# STM32L4P5xx register map
File version: 1.0
Registers are 32-bit, read-write, reset 0x0 unless marked. A register's access mark holds for its fields unless they carry their own. Offsets are from the block's base; [hi:lo] are bit positions; {n}, {i} and the like mark numbered series; 'fields as' and 'values as' point back to an identical list.

## HASH
Base 0x50060400
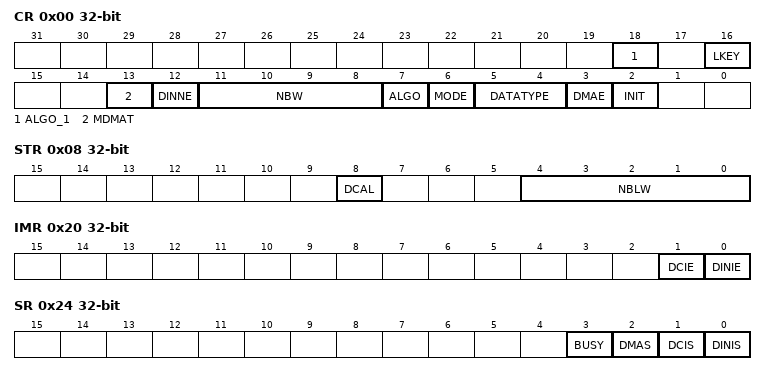
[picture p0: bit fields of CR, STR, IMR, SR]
0x00 CR — HASH control register
  [18] ALGO_1, [16] LKEY, [13] MDMAT, [12] DINNE, [11:8] NBW, [7] ALGO, [6] MODE, [5:4] DATATYPE, [3] DMAE, [2] INIT
0x04 DIN — HASH data input register
0x08 STR — HASH start register
  [8] DCAL, [4:0] NBLW
{0xC+4i} HR{i} (i=0..4) — HASH digest registers
0x20 IMR — HASH interrupt enable register
  [1] DCIE, [0] DINIE
0x24 SR — HASH status register
  [3] BUSY, [2] DMAS, [1] DCIS, [0] DINIS
{0xF8+4i} CSR{i} (i=0..53) — HASH context swap registers
{0x310+4i} DIGEST_HR{i} (i=0..7) — HASH digest registers

## RNG
Base 0x50060800
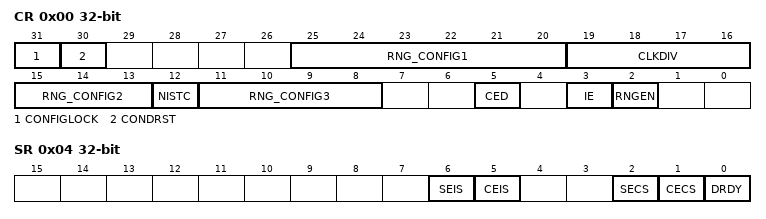
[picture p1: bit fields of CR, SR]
0x00 CR — RNG control register
  [31] CONFIGLOCK
  [30] CONDRST
  [25:20] RNG_CONFIG1
  [19:16] CLKDIV
    0=BY_1 (No clock division); 1=BY_2 (2 RNG clock cycles per internal RNG clock); 2=BY_4 (4 RNG clock cycles per internal RNG clock); 3=BY_8 (8 RNG clock cycles per internal RNG clock); 4=BY_16 (16 RNG clock cycles per internal RNG clock); 5=BY_32 (32 RNG clock cycles per internal RNG clock); 6=BY_64 (64 RNG clock cycles per internal RNG clock); 7=BY_128 (128 RNG clock cycles per internal RNG clock); 8=BY_256 (256 RNG clock cycles per internal RNG clock); 9=BY_512 (512 RNG clock cycles per internal RNG clock); 10=BY_1024 (1024 RNG clock cycles per internal RNG clock); 11=BY_2048 (2048 RNG clock cycles per internal RNG clock); 12=BY_4096 (4096 RNG clock cycles per internal RNG clock); 13=BY_8192 (8192 RNG clock cycles per internal RNG clock); 14=BY_16384 (16384 RNG clock cycles per internal RNG clock); 15=BY_32768 (32768 RNG clock cycles per internal RNG clock)
  [15:13] RNG_CONFIG2
  [12] NISTC
  [11:8] RNG_CONFIG3
  [5] CED
  [3] IE
  [2] RNGEN
0x04 SR — RNG status register
  [6] SEIS, [5] CEIS, [2] SECS, [1] CECS, [0] DRDY
0x08 DR — RNG data register
0x10 HTCR — RNG health test control register

## OCTOSPIM — OCTO Serial Peripheral Interface IO Manager
Base 0x50061C00
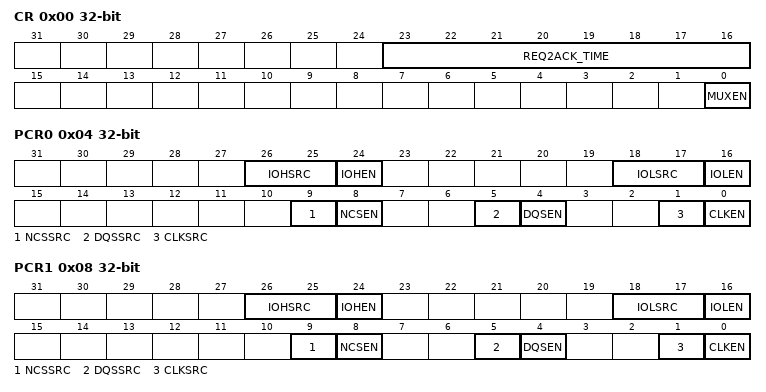
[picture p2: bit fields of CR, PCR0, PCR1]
0x00 CR — OCTOSPI IO Manager Control register
  [23:16] REQ2ACK_TIME — REQ to ACK time
  [0] MUXEN — Multiplexed mode enable
0x04 PCR0 — OCTOSPI IO Manager Port[1:2] Configuration register
  [26:25] IOHSRC — IO[7:4] Source for Port n
  [24] IOHEN — IO[7:4] Enable for Port n
  [18:17] IOLSRC — IO[3:0] Source for Port n
  [16] IOLEN — IO[3:0] Enable for Port n
  [9] NCSSRC — nCS Source for Port n
  [8] NCSEN — nCS Enable for Port n
  [5] DQSSRC — DQS Source for Port n
  [4] DQSEN — DQS Enable for Port n
  [1] CLKSRC — CLK/CLKn Source for Port n
  [0] CLKEN — CLK/CLKn Enable for Port n
0x08 PCR1 — OCTOSPI IO Manager Port[1:2] Configuration register
  fields as PCR0

## FMC_Bank1_R — Flexible Memory Controller
Base 0xA0000000
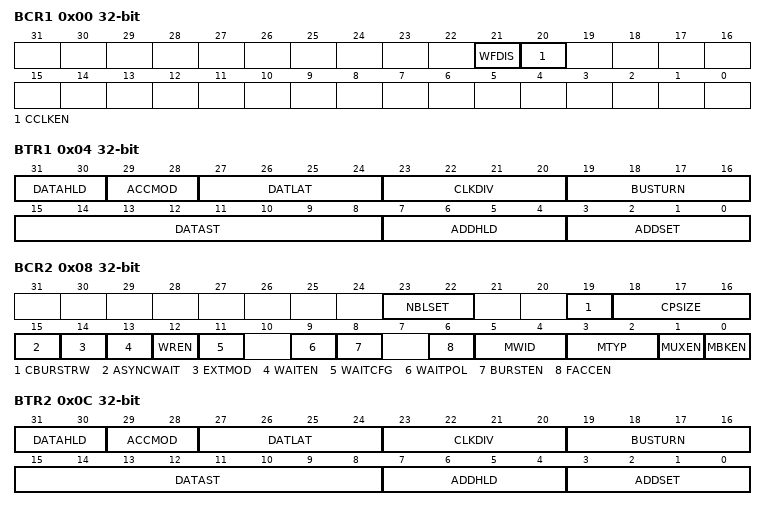
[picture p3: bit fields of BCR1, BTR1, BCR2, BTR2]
0x00 BCR1 — NOR/PSRAM chip-select control register(BCR) and chip-select timing register(BTR)
  [21] WFDIS — Write FIFO Disable
  [20] CCLKEN — Continuous clock enable
0x04 BTR1 — NOR/PSRAM chip-select control register(BCR) and chip-select timing register(BTR)
  [31:30] DATAHLD — DATAHLD[1:0] bits (Data hold phase duration)
  [29:28] ACCMOD — ACCMOD[1:0] bits (Access mode)
  [27:24] DATLAT — DATLAT[3:0] bits (Data latency)
  [23:20] CLKDIV — CLKDIV[3:0] bits (Clock divide ratio)
  [19:16] BUSTURN — BUSTURN[3:0] bits (Bus turnaround phase duration)
  [15:8] DATAST — DATAST [3:0] bits (Data-phase duration)
  [7:4] ADDHLD — ADDHLD[3:0] bits (Address-hold phase duration)
  [3:0] ADDSET — ADDSET[3:0] bits (Address setup phase duration)
0x08 BCR2 — NOR/PSRAM chip-select control register(BCR) and chip-select timing register(BTR)
  [23:22] NBLSET — Byte lane (NBL) setup
  [19] CBURSTRW — Write burst enable
  [18:16] CPSIZE — CRAM page size
  [15] ASYNCWAIT — Asynchronous wait
  [14] EXTMOD — Extended mode enable
  [13] WAITEN — Wait enable bit
  [12] WREN — Write enable bit
  [11] WAITCFG — Wait timing configuration
  [9] WAITPOL — Wait signal polarity bit
  [8] BURSTEN — Burst enable bit
  [6] FACCEN — Flash access enable
  [5:4] MWID — MWID[1:0] bits (Memory data bus width)
  [3:2] MTYP — MTYP[1:0] bits (Memory type)
  [1] MUXEN — Address/data multiplexing enable bit
  [0] MBKEN — Memory bank enable bit
0x0C BTR2 — NOR/PSRAM chip-select control register(BCR) and chip-select timing register(BTR)
  fields as BTR1
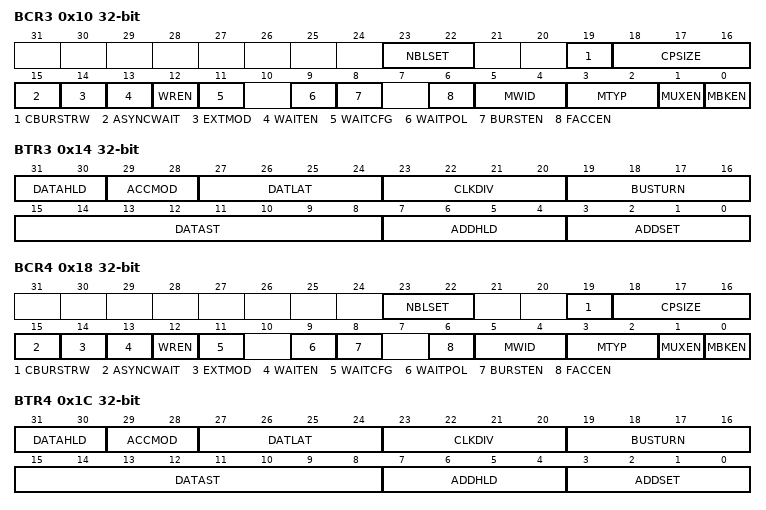
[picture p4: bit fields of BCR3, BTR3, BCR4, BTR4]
0x10 BCR3 — NOR/PSRAM chip-select control register(BCR) and chip-select timing register(BTR)
  fields as BCR2
0x14 BTR3 — NOR/PSRAM chip-select control register(BCR) and chip-select timing register(BTR)
  fields as BTR1
0x18 BCR4 — NOR/PSRAM chip-select control register(BCR) and chip-select timing register(BTR)
  fields as BCR2
0x1C BTR4 — NOR/PSRAM chip-select control register(BCR) and chip-select timing register(BTR)
  fields as BTR1
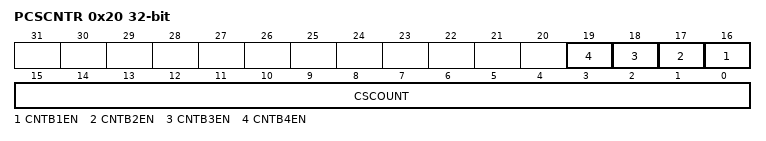
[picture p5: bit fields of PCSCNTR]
0x20 PCSCNTR — PSRAM chip-select counter register
  [n+15] CNTB{n}EN (n=1..4) — CNTB{n}EN bit (Counter Bank {n} enable)
  [15:0] CSCOUNT — CSCOUNT[15:0] bits (Chip select counter)

## FMC_Bank3_R — Flexible Memory Controller Bank3
Base 0xA0000080
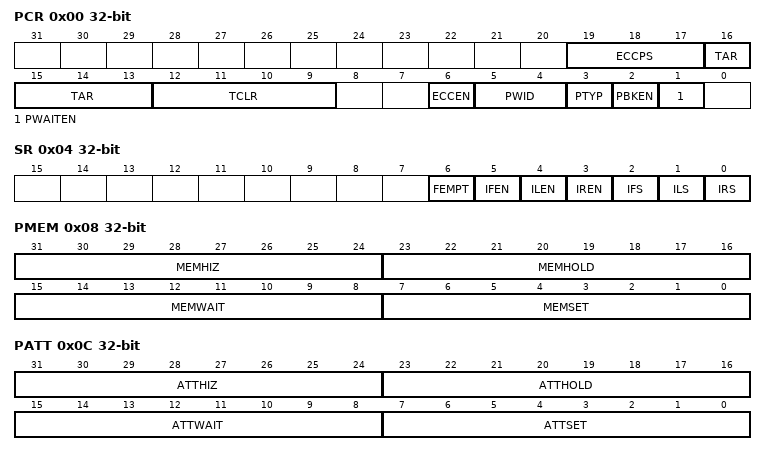
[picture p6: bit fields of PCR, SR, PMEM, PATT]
0x00 PCR — NAND Flash control register
  [19:17] ECCPS — ECCPS[1:0] bits (ECC page size)
  [16:13] TAR — TAR[3:0] bits (ALE to RE delay)
  [12:9] TCLR — TCLR[3:0] bits (CLE to RE delay)
  [6] ECCEN — ECC computation logic enable bit
  [5:4] PWID — PWID[1:0] bits (NAND Flash databus width)
  [3] PTYP — Memory type
  [2] PBKEN — NAND Flash memory bank enable bit
  [1] PWAITEN — Wait feature enable bit
0x04 SR — NAND Flash FIFO status and interrupt register
  [6] FEMPT — FIFO empty
  [5] IFEN — Interrupt Falling Edge detection Enable bit
  [4] ILEN — Interrupt Level detection Enable bit
  [3] IREN — Interrupt Rising Edge detection Enable bit
  [2] IFS — Interrupt Falling Edge status
  [1] ILS — Interrupt Level status
  [0] IRS — Interrupt Rising Edge status
0x08 PMEM — NAND Flash Common memory space timing register
  [31:24] MEMHIZ — MEMHIZ[7:0] bits (Common memory databus HiZ time)
  [23:16] MEMHOLD — MEMHOLD[7:0] bits (Common memory hold time)
  [15:8] MEMWAIT — MEMWAIT[7:0] bits (Common memory wait time)
  [7:0] MEMSET — MEMSET[7:0] bits (Common memory setup time)
0x0C PATT — NAND Flash Attribute memory space timing register
  [31:24] ATTHIZ — ATTHIZ[7:0] bits (Attribute memory databus HiZ time)
  [23:16] ATTHOLD — ATTHOLD[7:0] bits (Attribute memory hold time)
  [15:8] ATTWAIT — ATTWAIT[7:0] bits (Attribute memory wait time)
  [7:0] ATTSET — ATTSET[7:0] bits (Attribute memory setup time)
0x14 ECCR — NAND Flash ECC result registers
  [31:0] ECC — ECC result

## FMC_Bank1E_R — Flexible Memory Controller Bank1E
Base 0xA0000104
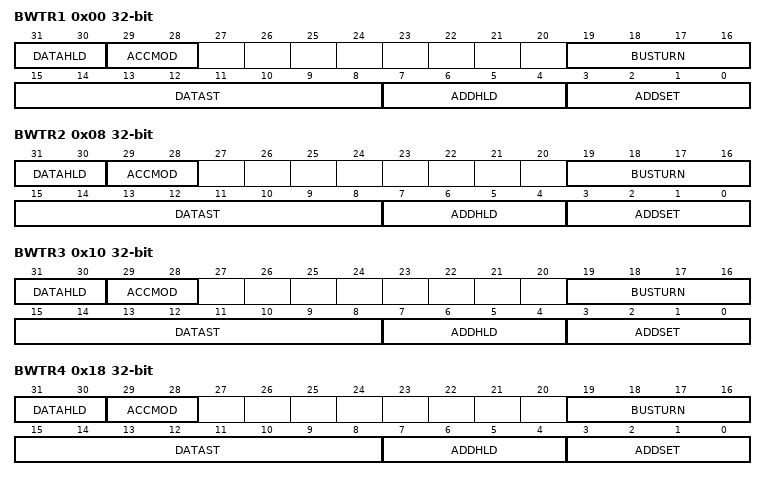
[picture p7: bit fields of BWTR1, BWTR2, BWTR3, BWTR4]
0x00 BWTR1 — NOR/PSRAM write timing registers
  [31:30] DATAHLD — DATAHLD[1:0] bits (Data hold phase duration)
  [29:28] ACCMOD — ACCMOD[1:0] bits (Access mode)
  [19:16] BUSTURN — BUSTURN[3:0] bits (Bus turnaround phase duration)
  [15:8] DATAST — DATAST [3:0] bits (Data-phase duration)
  [7:4] ADDHLD — ADDHLD[3:0] bits (Address-hold phase duration)
  [3:0] ADDSET — ADDSET[3:0] bits (Address setup phase duration)
0x08 BWTR2 — NOR/PSRAM write timing registers
  fields as BWTR1
0x10 BWTR3 — NOR/PSRAM write timing registers
  fields as BWTR1
0x18 BWTR4 — NOR/PSRAM write timing registers
  fields as BWTR1

## DBGMCU — Debug MCU
Base 0xE0042000
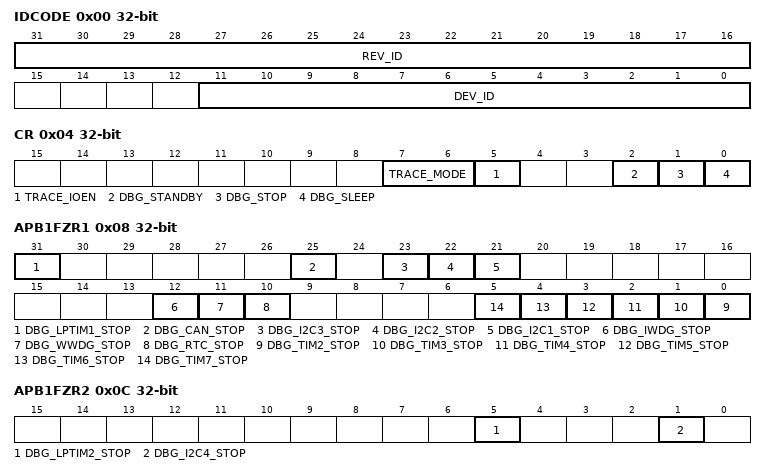
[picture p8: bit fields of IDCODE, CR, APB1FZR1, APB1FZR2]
0x00 IDCODE — MCU device ID code
  [31:16] REV_ID, [11:0] DEV_ID
0x04 CR — Debug MCU configuration register
  [7:6] TRACE_MODE, [5] TRACE_IOEN, [2] DBG_STANDBY, [1] DBG_STOP, [0] DBG_SLEEP
0x08 APB1FZR1 — Debug MCU APB1 freeze register 1
  [31] DBG_LPTIM1_STOP, [25] DBG_CAN_STOP, [23] DBG_I2C3_STOP, [22] DBG_I2C2_STOP, [21] DBG_I2C1_STOP, [12] DBG_IWDG_STOP, [11] DBG_WWDG_STOP, [10] DBG_RTC_STOP, [n-2] DBG_TIM{n}_STOP (n=2..7)
0x0C APB1FZR2 — Debug MCU APB1 freeze register 2
  [5] DBG_LPTIM2_STOP, [1] DBG_I2C4_STOP
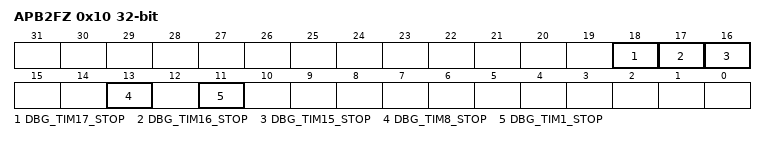
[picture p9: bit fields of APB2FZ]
0x10 APB2FZ — Debug MCU APB2 freeze register
  [18] DBG_TIM17_STOP, [17] DBG_TIM16_STOP, [16] DBG_TIM15_STOP, [13] DBG_TIM8_STOP, [11] DBG_TIM1_STOP
